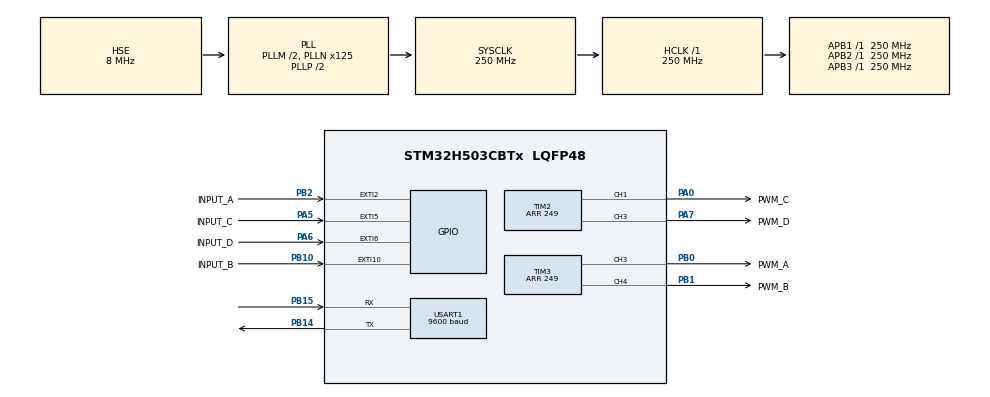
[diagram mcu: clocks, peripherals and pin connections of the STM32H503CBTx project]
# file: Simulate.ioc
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BOOTPATH.BootPathName=LEGACY
BOOTPATH.UserSelectedBootPath=LEGACY
Mcu.Family=STM32H5
Mcu.Name=STM32H503CBTx
Mcu.Package=LQFP48
NVIC.EXTI10_IRQn=true\:0\:0\:false\:false\:true\:true\:true\:true
NVIC.EXTI2_IRQn=true\:0\:0\:false\:false\:true\:true\:true\:true
NVIC.EXTI5_IRQn=true\:0\:0\:false\:false\:true\:true\:true\:true
NVIC.EXTI6_IRQn=true\:0\:0\:false\:false\:true\:true\:true\:true
NVIC.PriorityGroup=NVIC_PRIORITYGROUP_4
NVIC.TIM1_UP_IRQn=true\:1\:0\:true\:false\:true\:true\:true\:true
NVIC.TIM2_IRQn=true\:1\:0\:true\:false\:true\:true\:true\:true
NVIC.TIM3_IRQn=true\:1\:0\:true\:false\:true\:true\:true\:true
NVIC.TIM6_IRQn=true\:1\:0\:true\:false\:true\:true\:true\:true
NVIC.USART1_IRQn=true\:1\:0\:true\:false\:true\:true\:true\:true
PA0.GPIO_Label=PWM_C
PA0.Signal=S_TIM2_CH1
PA13(JTMS/SWDIO).Mode=Serial_Wire
PA13(JTMS/SWDIO).Signal=DEBUG_JTMS-SWDIO
PA14(JTCK/SWCLK).Mode=Serial_Wire
PA14(JTCK/SWCLK).Signal=DEBUG_JTCK-SWCLK
PA5.GPIO_Label=INPUT_C
PA5.GPIO_PuPd=GPIO_PULLDOWN
PA5.Signal=GPXTI5
PA6.GPIO_Label=INPUT_D
PA6.GPIO_PuPd=GPIO_PULLDOWN
PA6.Signal=GPXTI6
PA7.GPIO_Label=PWM_D
PA7.Signal=S_TIM2_CH3
PB0.GPIO_Label=PWM_A
PB0.Signal=S_TIM3_CH3
PB1.GPIO_Label=PWM_B
PB1.Signal=S_TIM3_CH4
PB10.GPIO_Label=INPUT_B
PB10.GPIO_PuPd=GPIO_PULLDOWN
PB10.Signal=GPXTI10
PB14.Mode=Asynchronous
PB14.Signal=USART1_TX
PB15.Mode=Asynchronous
PB15.Signal=USART1_RX
PB2.GPIO_Label=INPUT_A
PB2.GPIO_ModeDefaultEXTI=GPIO_MODE_IT_RISING
PB2.GPIO_PuPd=GPIO_PULLDOWN
PB2.Signal=GPXTI2
PH0-OSC_IN(PH0).Mode=HSE-External-Oscillator
PH0-OSC_IN(PH0).Signal=RCC_OSC_IN
PH1-OSC_OUT(PH1).Mode=HSE-External-Oscillator
PH1-OSC_OUT(PH1).Signal=RCC_OSC_OUT
ProjectManager.HeapSize=0x200
ProjectManager.StackSize=0x400
ProjectManager.TargetToolchain=MDK-ARM V5.37
RCC.ADCFreq_Value=250000000
RCC.AHBFreq_Value=250000000
RCC.APB1Freq_Value=250000000
RCC.APB1TimFreq_Value=250000000
RCC.APB2Freq_Value=250000000
RCC.APB2TimFreq_Value=250000000
RCC.APB3Freq_Value=250000000
RCC.CSI_VALUE=4000000
RCC.CortexFreq_Value=250000000
RCC.EPOD_VALUE=8000000
RCC.HCLKFreq_Value=250000000
RCC.HSE_VALUE=8000000
RCC.HSI48_VALUE=48000000
RCC.HSI_VALUE=64000000
RCC.LSE_VALUE=32768
RCC.LSIRC_VALUE=32000
RCC.PLLM=2
RCC.PLLN=125
RCC.PLLSourceVirtual=RCC_PLL1_SOURCE_HSE
RCC.SYSCLKFreq_VALUE=250000000
RCC.SYSCLKSource=RCC_SYSCLKSOURCE_PLLCLK
RCC.USBFreq_Value=48000000
RCC.VCOOutputFreq_Value=500000000
SH.S_TIM2_CH1.0=TIM2_CH1,PWM Generation1 CH1
SH.S_TIM2_CH3.0=TIM2_CH3,PWM Generation3 CH3
SH.S_TIM3_CH3.0=TIM3_CH3,PWM Generation3 CH3
SH.S_TIM3_CH4.0=TIM3_CH4,PWM Generation4 CH4
TIM1.AutoReloadPreload=TIM_AUTORELOAD_PRELOAD_ENABLE
TIM1.PeriodNoDither=9000
TIM2.AutoReloadPreload=TIM_AUTORELOAD_PRELOAD_ENABLE
TIM2.Channel-PWM\ Generation1\ CH1=TIM_CHANNEL_1
TIM2.Channel-PWM\ Generation3\ CH3=TIM_CHANNEL_3
TIM2.OCPolarity_1=TIM_OCPOLARITY_LOW
TIM2.OCPolarity_3=TIM_OCPOLARITY_LOW
TIM2.PeriodNoDither=249
TIM2.PulseNoDither_1=149
TIM2.PulseNoDither_3=149
TIM3.Channel-PWM\ Generation3\ CH3=TIM_CHANNEL_3
TIM3.Channel-PWM\ Generation4\ CH4=TIM_CHANNEL_4
TIM3.OCPolarity_3=TIM_OCPOLARITY_LOW
TIM3.OCPolarity_4=TIM_OCPOLARITY_LOW
TIM3.PeriodNoDither=249
TIM3.PulseNoDither_3=149
TIM3.PulseNoDither_4=149
TIM6.AutoReloadPreload=TIM_AUTORELOAD_PRELOAD_ENABLE
TIM6.PeriodNoDither=9010
USART1.BaudRate=9600
USART1.VirtualMode=VM_ASYNC
VP_BOOTPATH_VS_BOOTPATH.Mode=BP_Activate
VP_ICACHE_VS_ICACHE.Mode=DirectMappedCache
VP_MEMORYMAP_VS_MEMORYMAP.Mode=CurAppReg
VP_PWR_VS_DBSignals.Mode=DisableDeadBatterySignals
VP_PWR_VS_LPOM.Mode=PowerOptimisation
VP_PWR_VS_SECSignals.Mode=Security/Privilege
VP_TIM1_VS_ClockSourceINT.Mode=Internal
VP_TIM2_VS_ClockSourceINT.Mode=Internal
VP_TIM3_VS_ClockSourceINT.Mode=Internal
VP_TIM6_VS_ClockSourceINT.Mode=Enable_Timer
board=custom

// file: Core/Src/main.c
/* USER CODE BEGIN Header */
/**
  ******************************************************************************
  * @file           : main.c
  * @brief          : Main program body
  ******************************************************************************
  * @attention
  *
  * Copyright (c) 2025 STMicroelectronics.
  * All rights reserved.
  *
  * This software is licensed under terms that can be found in the LICENSE file
  * in the root directory of this software component.
  * If no LICENSE file comes with this software, it is provided AS-IS.
  *
  ******************************************************************************
  */
/* USER CODE END Header */
#include "main.h"
#include "icache.h"
#include "memorymap.h"
#include "tim.h"
#include "usart.h"
#include "gpio.h"

/* USER CODE BEGIN Includes */
#include "process.h"
#include "capture.h"
/* USER CODE END Includes */

/* USER CODE BEGIN PV */
extern uint8_t RxBuff[1];
/* USER CODE END PV */

void SystemClock_Config(void);

int main(void)
{

  /* MCU Configuration--------------------------------------------------------*/

  /* Reset of all peripherals, Initializes the Flash interface and the Systick. */
  HAL_Init();

  /* Configure the system clock */
  SystemClock_Config();

  /* Initialize all configured peripherals */
  MX_GPIO_Init();
  MX_ICACHE_Init();
  MX_USART1_UART_Init();
  MX_TIM3_Init();
  MX_TIM2_Init();
  MX_TIM1_Init();
  MX_TIM6_Init();
  /* USER CODE BEGIN 2 */
	Water_Disable();
	Get_Buffer_Init();
  /* USER CODE END 2 */

  /* Infinite loop */
  /* USER CODE BEGIN WHILE */
	HAL_TIM_PWM_Init(&htim3);
	HAL_TIM_PWM_Init(&htim2);
//	HAL_NVIC_EnableIRQ(EXTI2_IRQn);
//	HAL_NVIC_EnableIRQ(EXTI10_IRQn);
//	HAL_NVIC_EnableIRQ(EXTI5_IRQn);
//	HAL_NVIC_EnableIRQ(EXTI6_IRQn);
//	HAL_TIM_PWM_Start_IT(&htim3,TIM_CHANNEL_4); //Bģ�ⷢ��
//	HAL_TIM_PWM_Start_IT(&htim3,TIM_CHANNEL_3);//Aģ�ⷢ��
  while (1)
  {

//		Capture_Detect();
		Data_Process();
    /* USER CODE END WHILE */

  }
}

void SystemClock_Config(void)
{
  RCC_OscInitTypeDef RCC_OscInitStruct = {0};
  RCC_ClkInitTypeDef RCC_ClkInitStruct = {0};

  /** Configure the main internal regulator output voltage
  */
  __HAL_PWR_VOLTAGESCALING_CONFIG(PWR_REGULATOR_VOLTAGE_SCALE0);

  while(!__HAL_PWR_GET_FLAG(PWR_FLAG_VOSRDY)) {}

  /** Initializes the RCC Oscillators according to the specified parameters
  * in the RCC_OscInitTypeDef structure.
  */
  RCC_OscInitStruct.OscillatorType = RCC_OSCILLATORTYPE_HSE;
  RCC_OscInitStruct.HSEState = RCC_HSE_ON;
  RCC_OscInitStruct.PLL.PLLState = RCC_PLL_ON;
  RCC_OscInitStruct.PLL.PLLSource = RCC_PLL1_SOURCE_HSE;
  RCC_OscInitStruct.PLL.PLLM = 2;
  RCC_OscInitStruct.PLL.PLLN = 125;
  RCC_OscInitStruct.PLL.PLLP = 2;
  RCC_OscInitStruct.PLL.PLLQ = 2;
  RCC_OscInitStruct.PLL.PLLR = 2;
  RCC_OscInitStruct.PLL.PLLRGE = RCC_PLL1_VCIRANGE_2;
  RCC_OscInitStruct.PLL.PLLVCOSEL = RCC_PLL1_VCORANGE_WIDE;
  RCC_OscInitStruct.PLL.PLLFRACN = 0;
  if (HAL_RCC_OscConfig(&RCC_OscInitStruct) != HAL_OK)
  {
    Error_Handler();
  }

  /** Initializes the CPU, AHB and APB buses clocks
  */
  RCC_ClkInitStruct.ClockType = RCC_CLOCKTYPE_HCLK|RCC_CLOCKTYPE_SYSCLK
                              |RCC_CLOCKTYPE_PCLK1|RCC_CLOCKTYPE_PCLK2
                              |RCC_CLOCKTYPE_PCLK3;
  RCC_ClkInitStruct.SYSCLKSource = RCC_SYSCLKSOURCE_PLLCLK;
  RCC_ClkInitStruct.AHBCLKDivider = RCC_SYSCLK_DIV1;
  RCC_ClkInitStruct.APB1CLKDivider = RCC_HCLK_DIV1;
  RCC_ClkInitStruct.APB2CLKDivider = RCC_HCLK_DIV1;
  RCC_ClkInitStruct.APB3CLKDivider = RCC_HCLK_DIV1;

  if (HAL_RCC_ClockConfig(&RCC_ClkInitStruct, FLASH_LATENCY_5) != HAL_OK)
  {
    Error_Handler();
  }
}

void Error_Handler(void)
{
  __disable_irq();
  while (1)
  {
  }
}
